# MKL24Z4 register map
Vendor: Freescale Semiconductor, Inc.; Series: Kinetis_L; File version: 1.6
CPU: CM0PLUS r0p0, little endian, no MPU, no FPU, VTOR, 2 interrupt priority bits
Registers are 32-bit, read-write, reset 0x0 unless marked. A register's access mark holds for its fields unless they carry their own. Offsets are from the block's base; [hi:lo] are bit positions; {n}, {i} and the like mark numbered series.

## DMAMUX0 — DMA channel multiplexor
Base 0x40021000; register names take the prefix DMAMUX0_
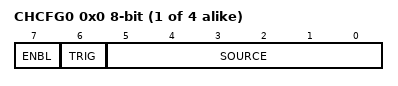
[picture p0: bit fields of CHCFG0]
{0x0+i} CHCFG{i} (i=0..3) 8-bit — Channel Configuration register
  [7] ENBL — DMA Channel Enable
    0=DMA channel is disabled. This mode is primarily used during configuration of the DMA Mux. The DMA has separate channel enables/disables, which should be used to disable or re-configure a DMA channel.; 1=DMA channel is enabled
  [6] TRIG — DMA Channel Trigger Enable
    0=Triggering is disabled. If triggering is disabled, and the ENBL bit is set, the DMA Channel will simply route the specified source to the DMA channel. (Normal mode); 1=Triggering is enabled. If triggering is enabled, and the ENBL bit is set, the DMAMUX is in Periodic Trigger mode.
  [5:0] SOURCE — DMA Channel Source (Slot)

## PIT — Periodic Interrupt Timer
Base 0x40037000; register names take the prefix PIT_
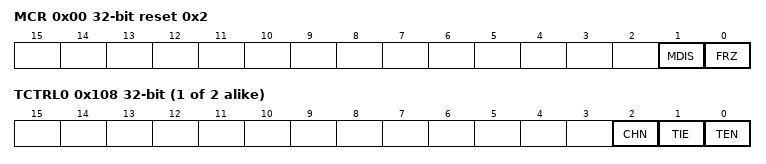
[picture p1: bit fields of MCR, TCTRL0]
0x00 MCR reset 0x2 — PIT Module Control Register
  [1] MDIS — Module Disable - (PIT section)
    0=Clock for standard PIT timers is enabled; 1=Clock for standard PIT timers is disabled
  [0] FRZ — Freeze
    0=Timers continue to run in Debug mode; 1=Timers are stopped in Debug mode
0xE0 LTMR64H ro — PIT Upper Lifetime Timer Register
  [31:0] LTH — Life Timer value
0xE4 LTMR64L ro — PIT Lower Lifetime Timer Register
  [31:0] LTL — Life Timer value
{0x100+0x10*i} LDVAL{i} (i=0..1) — Timer Load Value Register
  [31:0] TSV — Timer Start Value
{0x104+0x10*i} CVAL{i} (i=0..1) ro — Current Timer Value Register
  [31:0] TVL — Current Timer Value
{0x108+0x10*i} TCTRL{i} (i=0..1) — Timer Control Register
  [2] CHN — Chain Mode
    0=Timer is not chained; 1=Timer is chained to previous timer. For example, for Channel 2, if this field is set, Timer 2 is chained to Timer 1.
  [1] TIE — Timer Interrupt Enable
    0=Interrupt requests from Timer n are disabled; 1=Interrupt will be requested whenever TIF is set
  [0] TEN — Timer Enable
    0=Timer n is disabled; 1=Timer n is enabled
{0x10C+0x10*i} TFLG{i} (i=0..1) — Timer Flag Register
  [0] TIF — Timer Interrupt Flag
    0=Timeout has not yet occurred; 1=Timeout has occurred

## LPTMR0 — Low Power Timer
Base 0x40040000; register names take the prefix LPTMR0_
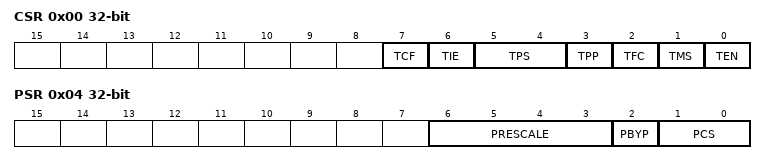
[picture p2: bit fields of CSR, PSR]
0x00 CSR — Low Power Timer Control Status Register
  [7] TCF — Timer Compare Flag
    0=The value of CNR is not equal to CMR and increments; 1=The value of CNR is equal to CMR and increments
  [6] TIE — Timer Interrupt Enable
    0=Timer interrupt disabled; 1=Timer interrupt enabled
  [5:4] TPS — Timer Pin Select
    {v}=Pulse counter input {v} is selected (v=0..3)
  [3] TPP — Timer Pin Polarity
    0=Pulse Counter input source is active-high, and the CNR will increment on the rising-edge; 1=Pulse Counter input source is active-low, and the CNR will increment on the falling-edge
  [2] TFC — Timer Free-Running Counter
    0=CNR is reset whenever TCF is set; 1=CNR is reset on overflow
  [1] TMS — Timer Mode Select
    0=Time Counter mode; 1=Pulse Counter mode
  [0] TEN — Timer Enable
    0=LPTMR is disabled and internal logic is reset; 1=LPTMR is enabled
0x04 PSR — Low Power Timer Prescale Register
  [6:3] PRESCALE — Prescale Value
    0=Prescaler divides the prescaler clock by 2; glitch filter does not support this configuration; 1=Prescaler divides the prescaler clock by 4; glitch filter recognizes change on input pin after 2 rising clock edges; 2=Prescaler divides the prescaler clock by 8; glitch filter recognizes change on input pin after 4 rising clock edges; 3=Prescaler divides the prescaler clock by 16; glitch filter recognizes change on input pin after 8 rising clock edges; 4=Prescaler divides the prescaler clock by 32; glitch filter recognizes change on input pin after 16 rising clock edges; 5=Prescaler divides the prescaler clock by 64; glitch filter recognizes change on input pin after 32 rising clock edges; 6=Prescaler divides the prescaler clock by 128; glitch filter recognizes change on input pin after 64 rising clock edges; 7=Prescaler divides the prescaler clock by 256; glitch filter recognizes change on input pin after 128 rising clock edges; 8=Prescaler divides the prescaler clock by 512; glitch filter recognizes change on input pin after 256 rising clock edges; 9=Prescaler divides the prescaler clock by 1024; glitch filter recognizes change on input pin after 512 rising clock edges; 10=Prescaler divides the prescaler clock by 2048; glitch filter recognizes change on input pin after 1024 rising clock edges; 11=Prescaler divides the prescaler clock by 4096; glitch filter recognizes change on input pin after 2048 rising clock edges; 12=Prescaler divides the prescaler clock by 8192; glitch filter recognizes change on input pin after 4096 rising clock edges; 13=Prescaler divides the prescaler clock by 16,384; glitch filter recognizes change on input pin after 8192 rising clock edges; 14=Prescaler divides the prescaler clock by 32,768; glitch filter recognizes change on input pin after 16,384 rising clock edges; 15=Prescaler divides the prescaler clock by 65,536; glitch filter recognizes change on input pin after 32,768 rising clock edges
  [2] PBYP — Prescaler Bypass
    0=Prescaler/glitch filter is enabled; 1=Prescaler/glitch filter is bypassed
  [1:0] PCS — Prescaler Clock Select
    {v}=Prescaler/glitch filter clock {v} selected (v=0..3)
0x08 CMR — Low Power Timer Compare Register
  [15:0] COMPARE — Compare Value
0x0C CNR — Low Power Timer Counter Register
  [15:0] COUNTER — Counter Value

## Notices in the file
Redistribution and use in source and binary forms, with or without modification,
are permitted provided that the following conditions are met:
o Redistributions of source code must retain the above copyright notice, this list
of conditions and the following disclaimer.
o Redistributions in binary form must reproduce the above copyright notice, this
list of conditions and the following disclaimer in the documentation and/or
other materials provided with the distribution.
o Neither the name of Freescale Semiconductor, Inc. nor the names of its
contributors may be used to endorse or promote products derived from this
software without specific prior written permission.
THIS SOFTWARE IS PROVIDED BY THE COPYRIGHT HOLDERS AND CONTRIBUTORS "AS IS" AND
ANY EXPRESS OR IMPLIED WARRANTIES, INCLUDING, BUT NOT LIMITED TO, THE IMPLIED
WARRANTIES OF MERCHANTABILITY AND FITNESS FOR A PARTICULAR PURPOSE ARE
DISCLAIMED. IN NO EVENT SHALL THE COPYRIGHT HOLDER OR CONTRIBUTORS BE LIABLE FOR
ANY DIRECT, INDIRECT, INCIDENTAL, SPECIAL, EXEMPLARY, OR CONSEQUENTIAL DAMAGES
(INCLUDING, BUT NOT LIMITED TO, PROCUREMENT OF SUBSTITUTE GOODS OR SERVICES;
LOSS OF USE, DATA, OR PROFITS; OR BUSINESS INTERRUPTION) HOWEVER CAUSED AND ON
ANY THEORY OF LIABILITY, WHETHER IN CONTRACT, STRICT LIABILITY, OR TORT
(INCLUDING NEGLIGENCE OR OTHERWISE) ARISING IN ANY WAY OUT OF THE USE OF THIS
SOFTWARE, EVEN IF ADVISED OF THE POSSIBILITY OF SUCH DAMAGE.
